AUTOSAR XML (schema 00044)
package /E40_Platform_System_SystemPackage/Components
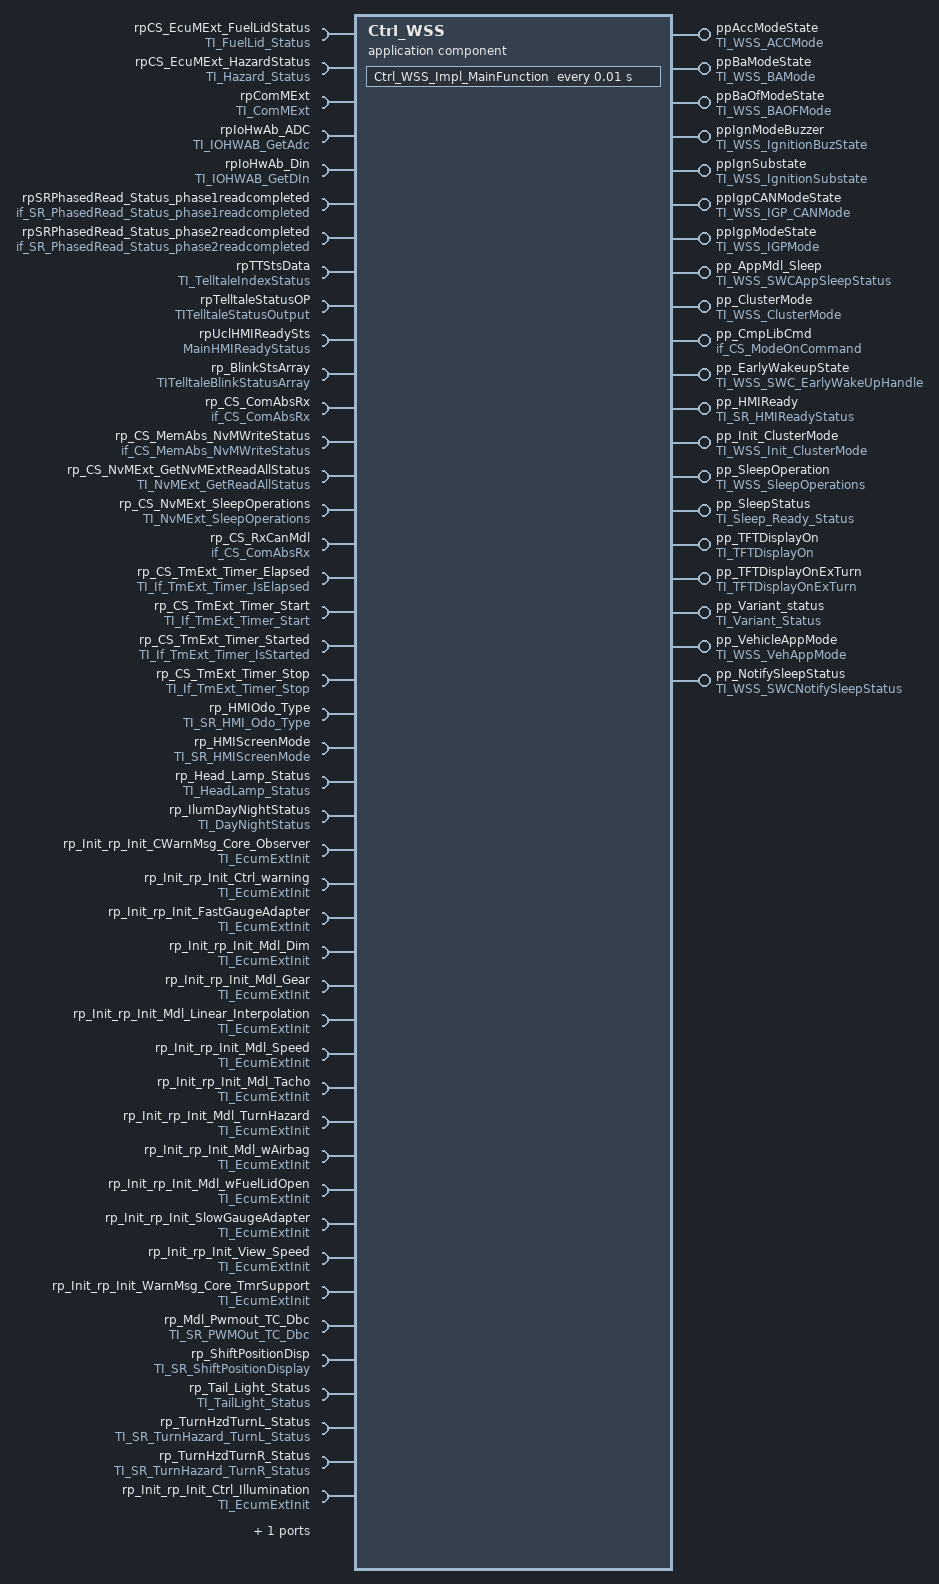
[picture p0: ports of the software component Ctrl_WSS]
  application sw component type Ctrl_WSS
    19 x provide port:
      ppAccModeState: nonqueued-sender-com-spec{data-element=WSSAccState, init-value=constant-reference=Ctrl_WSSWSSAccStateValue0}, provided-interface=TI_WSS_ACCMode
      ppBaModeState: nonqueued-sender-com-spec{data-element=WSSBaState, init-value=constant-reference=Ctrl_WSSWSSBaStateValue0}, provided-interface=TI_WSS_BAMode
      ppBaOfModeState: nonqueued-sender-com-spec{data-element=WSSBaOfState, init-value=constant-reference=Ctrl_WSSWSSBaOfStateValue0}, provided-interface=TI_WSS_BAOFMode
      ppIgnModeBuzzer: nonqueued-sender-com-spec{data-element=IgnitioBuznstate, init-value=constant-reference=Ctrl_WSSIgnitioBuznstateValue0}, provided-interface=TI_WSS_IgnitionBuzState
      ppIgnSubstate: nonqueued-sender-com-spec{data-element=IgnitionSubstate, init-value=constant-reference=Ctrl_WSSIgnitionSubstateValue0}, provided-interface=TI_WSS_IgnitionSubstate
      ppIgpCANModeState: nonqueued-sender-com-spec{data-element=WSSIGPCANState, init-value=constant-reference=Ctrl_WSSWSSIGPCANStateValue0}, provided-interface=TI_WSS_IGP_CANMode
      ppIgpModeState: nonqueued-sender-com-spec{data-element=WSSIGPState, init-value=constant-reference=Ctrl_WSSWSSIGPStateValue0}, provided-interface=TI_WSS_IGPMode
      pp_AppMdl_Sleep: server-com-spec{operation=SWCSleepStatus, queue-length=1}, provided-interface=TI_WSS_SWCAppSleepStatus
      pp_ClusterMode: nonqueued-sender-com-spec{data-element=WSSCurrentClusterMode, init-value=constant-reference=Ctrl_WSSWSSCurrentClusterModeValue0}, provided-interface=TI_WSS_ClusterMode
      pp_CmpLibCmd: server-com-spec{operation=Impl_OnCommand, queue-length=1}, provided-interface=if_CS_ModeOnCommand
      pp_EarlyWakeupState: server-com-spec{operation=SWCEarlyWakeUpHandle, queue-length=1}, provided-interface=TI_WSS_SWC_EarlyWakeUpHandle
      pp_HMIReady: nonqueued-sender-com-spec{data-element=HMI_ReadyStatus, init-value=constant-reference=Ctrl_WSSHMI_ReadyStatusValue0}, provided-interface=TI_SR_HMIReadyStatus
      pp_Init_ClusterMode: nonqueued-sender-com-spec{data-element=WSSCurrentClusterInitMode, init-value=constant-reference=Ctrl_WSSWSSCurrentClusterInitModeValue0}, provided-interface=TI_WSS_Init_ClusterMode
      pp_SleepOperation: provided-interface=TI_WSS_SleepOperations
        provided-com-specs:
          operation=CtrlWSS_CancelSleep, queue-length=1
          operation=CtrlWSS_ReadytoSleep, queue-length=1
          operation=CtrlWSS_RequestSleep, queue-length=1
      pp_SleepStatus: nonqueued-sender-com-spec{data-element=Sleep_Status, init-value=constant-reference=Ctrl_WSSSleep_StatusValue0}, provided-interface=TI_Sleep_Ready_Status
      pp_TFTDisplayOn: nonqueued-sender-com-spec{data-element=TFTDisplayOn, init-value=constant-reference=Ctrl_WSSTFTDisplayOnValue0}, provided-interface=TI_TFTDisplayOn
      pp_TFTDisplayOnExTurn: nonqueued-sender-com-spec{data-element=TFTDisplayOnExTurn, init-value=constant-reference=Ctrl_WSSTFTDisplayOnExTurnValue0}, provided-interface=TI_TFTDisplayOnExTurn
      pp_Variant_status: server-com-spec{operation=GetVariant_Status, queue-length=1}, provided-interface=TI_Variant_Status
      pp_VehicleAppMode: nonqueued-sender-com-spec{data-element=WSSCurrentVehicleState, init-value=constant-reference=Ctrl_WSSWSSCurrentVehicleStateValue0}, provided-interface=TI_WSS_VehAppMode
    45 x require port:
      rpCS_EcuMExt_FuelLidStatus: queued-receiver-com-spec{data-element=FuelLidStatus, queue-length=15}, required-interface=TI_FuelLid_Status
      rpCS_EcuMExt_HazardStatus: queued-receiver-com-spec{data-element=HazardStatus, queue-length=15}, required-interface=TI_Hazard_Status
      rpComMExt: required-interface=TI_ComMExt
        required-com-specs:
          CAN_ActivateSilentCommunication
          CAN_CommControlActivateRx
          CAN_CommControlActivateTx
          CAN_CommControlDeActivateRx
          CAN_CommControlDeActivateTx
          CAN_CommControlSetDone
          CAN_DeActivateSilentCommunication
          CAN_GetCurrentComMode
          CAN_ReleaseCommunication
          CAN_RequestCommunication
          GetBusOffStatus
          Get_MCAN_ERR_PIN_Status
          Init
      rpIoHwAb_ADC: required-com-specs=[GetAsyncRawAdc, GetProcessedAdc, GetSyncRawAdc], required-interface=TI_IOHWAB_GetAdc
      rpIoHwAb_Din: required-com-specs=[GetAsyncRawInput, GetInputGroup, GetProcessedInput, GetSyncRawInput], required-interface=TI_IOHWAB_GetDIn
      rpSRPhasedRead_Status_phase1readcompleted: nonqueued-receiver-com-spec{data-element=PhasedRead_Status_phase1readcompleted, init-value=constant-reference=Ctrl_WSSPhasedRead_Status_phase1readcompletedValue0}, required-interface=if_SR_PhasedRead_Status_phase1readcompleted
      rpSRPhasedRead_Status_phase2readcompleted: nonqueued-receiver-com-spec{data-element=PhasedRead_Status_phase2readcompleted, init-value=constant-reference=Ctrl_WSSPhasedRead_Status_phase2readcompletedValue0}, required-interface=if_SR_PhasedRead_Status_phase2readcompleted
      rpTTStsData: required-interface=TI_TelltaleIndexStatus
        required-com-specs:
          data-element=TTIndex, init-value=constant-reference=Ctrl_WSSTTIndexValue0
          data-element=TTStatus, init-value=constant-reference=Ctrl_WSSTTStatusValue0
      rpTelltaleStatusOP: nonqueued-receiver-com-spec{data-element=TelltaleOpArray, init-value=constant-reference=Ctrl_WSSTelltaleOpArrayValue0}, required-interface=TITelltaleStatusOutput
      rpUclHMIReadySts: queued-receiver-com-spec{data-element=MainHMIReadyStatusData, queue-length=5}, required-interface=MainHMIReadyStatus
      rp_BlinkStsArray: required-interface=TITelltaleBlinkStatusArray
        required-com-specs:
          data-element=TTBlinkStatusArray, init-value=constant-reference=Ctrl_WSSTTBlinkStatusArrayValue0
          data-element=TTdummyDataForTypes, init-value=constant-reference=Ctrl_WSSTTdummyDataForTypesValue0
      rp_CS_ComAbsRx: required-interface=if_CS_ComAbsRx
        required-com-specs:
          RxCan_GetSignalValue
          RxCan_GetSignalValueU8Arr
          RxCan_SetSignalInitValue
          RxCan_SetSignalInitValueU8Arr
          RxCan_SignalClearJustRcvdStatus
          RxCan_SignalGetJustRcvdStatus
          RxCan_SignalInvalidProcessingControl
          RxCan_SignalMissingProcessingControl
          RxCan_SignalNRProcessingControl
      rp_CS_MemAbs_NvMWriteStatus: client-com-spec=NvmWriteStatus, required-interface=if_CS_MemAbs_NvMWriteStatus
      rp_CS_NvMExt_GetNvMExtReadAllStatus: client-com-spec=NvmExt_GetNvMReadAllStatus, required-interface=TI_NvMExt_GetReadAllStatus
      rp_CS_NvMExt_SleepOperations: required-com-specs=[NvMExt_CancelSleep, NvMExt_ReadytoSleep, NvMExt_RequestSleep], required-interface=TI_NvMExt_SleepOperations
      rp_CS_RxCanMdl: required-interface=if_CS_ComAbsRx
        required-com-specs:
          RxCan_GetSignalValue
          RxCan_GetSignalValueU8Arr
          RxCan_SetSignalInitValue
          RxCan_SetSignalInitValueU8Arr
          RxCan_SignalClearJustRcvdStatus
          RxCan_SignalGetJustRcvdStatus
          RxCan_SignalInvalidProcessingControl
          RxCan_SignalMissingProcessingControl
          RxCan_SignalNRProcessingControl
      rp_CS_TmExt_Timer_Elapsed: client-com-spec=Timer_IsElapsed, required-interface=TI_If_TmExt_Timer_IsElapsed
      rp_CS_TmExt_Timer_Start: client-com-spec=Timer_Start, required-interface=TI_If_TmExt_Timer_Start
      rp_CS_TmExt_Timer_Started: client-com-spec=Timer_IsStarted, required-interface=TI_If_TmExt_Timer_IsStarted
      rp_CS_TmExt_Timer_Stop: client-com-spec=Timer_Stop, required-interface=TI_If_TmExt_Timer_Stop
      rp_HMIOdo_Type: nonqueued-receiver-com-spec{data-element=HMI_OdoType, init-value=constant-reference=Ctrl_WSSHMI_OdoTypeValue0}, required-interface=TI_SR_HMI_Odo_Type
      rp_HMIScreenMode: nonqueued-receiver-com-spec{data-element=HMIScreenMode_Status, init-value=constant-reference=Ctrl_WSSHMIScreenMode_StatusValue0}, required-interface=TI_SR_HMIScreenMode
      rp_Head_Lamp_Status: nonqueued-receiver-com-spec{data-element=Head_Lamp_st, init-value=constant-reference=Ctrl_WSSHead_Lamp_stValue0}, required-interface=TI_HeadLamp_Status
      rp_IlumDayNightStatus: nonqueued-receiver-com-spec{data-element=illumDNStatus, init-value=constant-reference=Ctrl_WSSillumDNStatusValue0}, required-interface=TI_DayNightStatus
      rp_Init_rp_Init_CWarnMsg_Core_Observer: client-com-spec=Init, required-interface=TI_EcumExtInit
      rp_Init_rp_Init_Ctrl_warning: client-com-spec=Init, required-interface=TI_EcumExtInit
      rp_Init_rp_Init_FastGaugeAdapter: client-com-spec=Init, required-interface=TI_EcumExtInit
      rp_Init_rp_Init_Mdl_Dim: client-com-spec=Init, required-interface=TI_EcumExtInit
      rp_Init_rp_Init_Mdl_Gear: client-com-spec=Init, required-interface=TI_EcumExtInit
      rp_Init_rp_Init_Mdl_Linear_Interpolation: client-com-spec=Init, required-interface=TI_EcumExtInit
      rp_Init_rp_Init_Mdl_Speed: client-com-spec=Init, required-interface=TI_EcumExtInit
      rp_Init_rp_Init_Mdl_Tacho: client-com-spec=Init, required-interface=TI_EcumExtInit
      rp_Init_rp_Init_Mdl_TurnHazard: client-com-spec=Init, required-interface=TI_EcumExtInit
      rp_Init_rp_Init_Mdl_wAirbag: client-com-spec=Init, required-interface=TI_EcumExtInit
      rp_Init_rp_Init_Mdl_wFuelLidOpen: client-com-spec=Init, required-interface=TI_EcumExtInit
      rp_Init_rp_Init_SlowGaugeAdapter: client-com-spec=Init, required-interface=TI_EcumExtInit
      rp_Init_rp_Init_View_Speed: client-com-spec=Init, required-interface=TI_EcumExtInit
      rp_Init_rp_Init_WarnMsg_Core_TmrSupport: client-com-spec=Init, required-interface=TI_EcumExtInit
      rp_Mdl_Pwmout_TC_Dbc: nonqueued-receiver-com-spec{data-element=PWMOut_TC_Dbc, init-value=constant-reference=Ctrl_WSSPWMOut_TC_DbcValue0}, required-interface=TI_SR_PWMOut_TC_Dbc
      rp_ShiftPositionDisp: nonqueued-receiver-com-spec{data-element=ShiftPositionDisplay, init-value=constant-reference=Ctrl_WSSShiftPositionDisplayValue0}, required-interface=TI_SR_ShiftPositionDisplay
      rp_Tail_Light_Status: nonqueued-receiver-com-spec{data-element=Tail_Light_st, init-value=constant-reference=Ctrl_WSSTail_Light_stValue0}, required-interface=TI_TailLight_Status
      rp_TurnHzdTurnL_Status: nonqueued-receiver-com-spec{data-element=LeftIndicatorSts, init-value=constant-reference=Ctrl_WSSLeftIndicatorStsValue0}, required-interface=TI_SR_TurnHazard_TurnL_Status
      rp_TurnHzdTurnR_Status: nonqueued-receiver-com-spec{data-element=RightIndicatorSts, init-value=constant-reference=Ctrl_WSSRightIndicatorStsValue0}, required-interface=TI_SR_TurnHazard_TurnR_Status
      rp_Init_rp_Init_Ctrl_Illumination: client-com-spec=Init, required-interface=TI_EcumExtInit
      rpSRPhasedRead_Status_phase3readcompleted: nonqueued-receiver-com-spec{data-element=PhasedRead_Status_phase3readcompleted, init-value=constant-reference=Ctrl_WSSPhasedRead_Status_phase3readcompletedValue0}, required-interface=if_SR_PhasedRead_Status_phase3readcompleted
    provide port pp_NotifySleepStatus: server-com-spec{operation=CtrlWSS_NotifyNetworkSleep, queue-length=1}, provided-interface=TI_WSS_SWCNotifySleepStatus
    behavior IB_Ctrl_WSS
      4 x operation invoked event:
        OIE_pp_SleepOperation_CtrlWSS_CancelSleepTrigByCtrlWSS_CancelSleep: start-on-event=CtrlWSS_CancelSleep, operation=pp_SleepOperation.CtrlWSS_CancelSleep
        OIE_pp_SleepOperation_CtrlWSS_ReadytoSleepTrigByCtrlWSS_ReadytoSleep: start-on-event=CtrlWSS_ReadytoSleep, operation=pp_SleepOperation.CtrlWSS_ReadytoSleep
        OIE_pp_SleepOperation_CtrlWSS_RequestSleepTrigByCtrlWSS_RequestSleep: start-on-event=CtrlWSS_RequestSleep, operation=pp_SleepOperation.CtrlWSS_RequestSleep
        OIE_pp_Variant_status_Ctrl_WSS_GetVariant_StatusTrigByGetVariant_Status: start-on-event=Ctrl_WSS_GetVariant_Status, operation=pp_Variant_status.GetVariant_Status
      timing event TECtrl_WSS_Impl_MainFunction: start-on-event=Ctrl_WSS_Impl_MainFunction, period=0.01
      4 x operation invoked event:
        OIE_pp_CmpLibCmd_Ctrl_WSS_Impl_OnCommandTrigByImpl_OnCommand: start-on-event=Ctrl_WSS_Impl_OnCommand, operation=pp_CmpLibCmd.Impl_OnCommand
        OIE_pp_EarlyWakeupState_Ctrl_WSS_SWCEarlyWakeUpHandleTrigBySWCEarlyWakeUpHandle: start-on-event=Ctrl_WSS_SWCEarlyWakeUpHandle, operation=pp_EarlyWakeupState.SWCEarlyWakeUpHandle
        OIE_pp_AppMdl_Sleep_Ctrl_WSS_SWCSleepStatusTrigBySWCSleepStatus: start-on-event=Ctrl_WSS_SWCSleepStatus, operation=pp_AppMdl_Sleep.SWCSleepStatus
        OIE_pp_NotifySleepStatus_Ctrl_WSS_CtrlWSS_NotifyNetworkSleepTrigByCtrlWSS_NotifyNetworkSleep: start-on-event=Ctrl_WSS_CtrlWSS_NotifyNetworkSleep, operation=pp_NotifySleepStatus.CtrlWSS_NotifyNetworkSleep
      port-api-options:
        enable-take-address=false, indirect-api=false, port=ppAccModeState
        enable-take-address=false, indirect-api=false, port=ppBaModeState
        enable-take-address=false, indirect-api=false, port=ppBaOfModeState
        enable-take-address=false, indirect-api=false, port=ppIgnModeBuzzer
        enable-take-address=false, indirect-api=false, port=ppIgnSubstate
        enable-take-address=false, indirect-api=false, port=ppIgpCANModeState
        enable-take-address=false, indirect-api=false, port=ppIgpModeState
        enable-take-address=false, indirect-api=false, port=pp_AppMdl_Sleep
        enable-take-address=false, indirect-api=false, port=pp_ClusterMode
        enable-take-address=false, indirect-api=false, port=pp_CmpLibCmd
        enable-take-address=false, indirect-api=false, port=pp_EarlyWakeupState
        enable-take-address=false, indirect-api=false, port=pp_HMIReady
        enable-take-address=false, indirect-api=false, port=pp_Init_ClusterMode
        enable-take-address=false, indirect-api=false, port=pp_SleepOperation
        enable-take-address=false, indirect-api=false, port=pp_SleepStatus
        enable-take-address=false, indirect-api=false, port=pp_TFTDisplayOn
        enable-take-address=false, indirect-api=false, port=pp_TFTDisplayOnExTurn
        enable-take-address=false, indirect-api=false, port=pp_Variant_status
        enable-take-address=false, indirect-api=false, port=pp_VehicleAppMode
        enable-take-address=false, indirect-api=false, port=rpCS_EcuMExt_FuelLidStatus
        enable-take-address=false, indirect-api=false, port=rpCS_EcuMExt_HazardStatus
        enable-take-address=false, indirect-api=false, port=rpComMExt
        enable-take-address=false, indirect-api=false, port=rpIoHwAb_ADC
        enable-take-address=false, indirect-api=false, port=rpIoHwAb_Din
        enable-take-address=false, indirect-api=false, port=rpSRPhasedRead_Status_phase1readcompleted
        enable-take-address=false, indirect-api=false, port=rpSRPhasedRead_Status_phase2readcompleted
        enable-take-address=false, indirect-api=false, port=rpTTStsData
        enable-take-address=false, indirect-api=false, port=rpTelltaleStatusOP
        enable-take-address=false, indirect-api=false, port=rpUclHMIReadySts
        enable-take-address=false, indirect-api=false, port=rp_BlinkStsArray
        enable-take-address=false, indirect-api=false, port=rp_CS_ComAbsRx
        enable-take-address=false, indirect-api=false, port=rp_CS_MemAbs_NvMWriteStatus
        enable-take-address=false, indirect-api=false, port=rp_CS_NvMExt_GetNvMExtReadAllStatus
        enable-take-address=false, indirect-api=false, port=rp_CS_NvMExt_SleepOperations
        enable-take-address=false, indirect-api=false, port=rp_CS_RxCanMdl
        enable-take-address=false, indirect-api=false, port=rp_CS_TmExt_Timer_Elapsed
        enable-take-address=false, indirect-api=false, port=rp_CS_TmExt_Timer_Start
        enable-take-address=false, indirect-api=false, port=rp_CS_TmExt_Timer_Started
        enable-take-address=false, indirect-api=false, port=rp_CS_TmExt_Timer_Stop
        enable-take-address=false, indirect-api=false, port=rp_HMIOdo_Type
        enable-take-address=false, indirect-api=false, port=rp_HMIScreenMode
        enable-take-address=false, indirect-api=false, port=rp_Head_Lamp_Status
        enable-take-address=false, indirect-api=false, port=rp_IlumDayNightStatus
        enable-take-address=false, indirect-api=false, port=rp_Init_rp_Init_CWarnMsg_Core_Observer
        enable-take-address=false, indirect-api=false, port=rp_Init_rp_Init_Ctrl_warning
        enable-take-address=false, indirect-api=false, port=rp_Init_rp_Init_FastGaugeAdapter
        enable-take-address=false, indirect-api=false, port=rp_Init_rp_Init_Mdl_Dim
        enable-take-address=false, indirect-api=false, port=rp_Init_rp_Init_Mdl_Gear
        enable-take-address=false, indirect-api=false, port=rp_Init_rp_Init_Mdl_Linear_Interpolation
        enable-take-address=false, indirect-api=false, port=rp_Init_rp_Init_Mdl_Speed
        enable-take-address=false, indirect-api=false, port=rp_Init_rp_Init_Mdl_Tacho
        enable-take-address=false, indirect-api=false, port=rp_Init_rp_Init_Mdl_TurnHazard
        enable-take-address=false, indirect-api=false, port=rp_Init_rp_Init_Mdl_wAirbag
        enable-take-address=false, indirect-api=false, port=rp_Init_rp_Init_Mdl_wFuelLidOpen
        enable-take-address=false, indirect-api=false, port=rp_Init_rp_Init_SlowGaugeAdapter
        enable-take-address=false, indirect-api=false, port=rp_Init_rp_Init_View_Speed
        enable-take-address=false, indirect-api=false, port=rp_Init_rp_Init_WarnMsg_Core_TmrSupport
        enable-take-address=false, indirect-api=false, port=rp_Mdl_Pwmout_TC_Dbc
        enable-take-address=false, indirect-api=false, port=rp_ShiftPositionDisp
        enable-take-address=false, indirect-api=false, port=rp_Tail_Light_Status
        enable-take-address=false, indirect-api=false, port=rp_TurnHzdTurnL_Status
        enable-take-address=false, indirect-api=false, port=rp_TurnHzdTurnR_Status
        enable-take-address=false, indirect-api=false, port=rp_Init_rp_Init_Ctrl_Illumination
        enable-take-address=false, indirect-api=false, port=rpSRPhasedRead_Status_phase3readcompleted
        enable-take-address=false, indirect-api=false, port=pp_NotifySleepStatus
      9 x runnable, all with can-be-invoked-concurrently=true:
        CtrlWSS_CancelSleep
        CtrlWSS_ReadytoSleep
        CtrlWSS_RequestSleep
        Ctrl_WSS_GetVariant_Status
        Ctrl_WSS_Impl_MainFunction
          data-receive-point-by-arguments:
            20 x access:
              DRP_rpCS_EcuMExt_FuelLidStatus_FuelLidStatus: accessed-variable=rpCS_EcuMExt_FuelLidStatus.FuelLidStatus
              DRP_rpCS_EcuMExt_HazardStatus_HazardStatus: accessed-variable=rpCS_EcuMExt_HazardStatus.HazardStatus
              DRA_rpSRPhasedRead_Status_phase1readcompleted_PhasedRead_Status_phase1readcompleted: accessed-variable=rpSRPhasedRead_Status_phase1readcompleted.PhasedRead_Status_phase1readcompleted
              DRA_rpSRPhasedRead_Status_phase2readcompleted_PhasedRead_Status_phase2readcompleted: accessed-variable=rpSRPhasedRead_Status_phase2readcompleted.PhasedRead_Status_phase2readcompleted
              DRA_rpTTStsData_TTIndex: accessed-variable=rpTTStsData.TTIndex
              DRA_rpTTStsData_TTStatus: accessed-variable=rpTTStsData.TTStatus
              DRA_rpTelltaleStatusOP_TelltaleOpArray: accessed-variable=rpTelltaleStatusOP.TelltaleOpArray
              DRA_rp_BlinkStsArray_TTBlinkStatusArray: accessed-variable=rp_BlinkStsArray.TTBlinkStatusArray
              DRA_rp_BlinkStsArray_TTdummyDataForTypes: accessed-variable=rp_BlinkStsArray.TTdummyDataForTypes
              DRA_rp_HMIOdo_Type_HMI_OdoType: accessed-variable=rp_HMIOdo_Type.HMI_OdoType
              DRA_rp_HMIScreenMode_HMIScreenMode_Status: accessed-variable=rp_HMIScreenMode.HMIScreenMode_Status
              DRA_rp_Head_Lamp_Status_Head_Lamp_st: accessed-variable=rp_Head_Lamp_Status.Head_Lamp_st
              DRA_rp_IlumDayNightStatus_illumDNStatus: accessed-variable=rp_IlumDayNightStatus.illumDNStatus
              DRA_rp_Mdl_Pwmout_TC_Dbc_PWMOut_TC_Dbc: accessed-variable=rp_Mdl_Pwmout_TC_Dbc.PWMOut_TC_Dbc
              DRA_rp_ShiftPositionDisp_ShiftPositionDisplay: accessed-variable=rp_ShiftPositionDisp.ShiftPositionDisplay
              DRA_rp_Tail_Light_Status_Tail_Light_st: accessed-variable=rp_Tail_Light_Status.Tail_Light_st
              DRA_rp_TurnHzdTurnL_Status_LeftIndicatorSts: accessed-variable=rp_TurnHzdTurnL_Status.LeftIndicatorSts
              DRA_rp_TurnHzdTurnR_Status_RightIndicatorSts: accessed-variable=rp_TurnHzdTurnR_Status.RightIndicatorSts
              DRP_rpUclHMIReadySts_MainHMIReadyStatusData: accessed-variable=rpUclHMIReadySts.MainHMIReadyStatusData
              DRA_rpSRPhasedRead_Status_phase3readcompleted_PhasedRead_Status_phase3readcompleted: accessed-variable=rpSRPhasedRead_Status_phase3readcompleted.PhasedRead_Status_phase3readcompleted
          data-send-points:
            14 x access:
              DWA_ppAccModeState_WSSAccState: accessed-variable=ppAccModeState.WSSAccState
              DWA_ppBaModeState_WSSBaState: accessed-variable=ppBaModeState.WSSBaState
              DWA_ppBaOfModeState_WSSBaOfState: accessed-variable=ppBaOfModeState.WSSBaOfState
              DWA_ppIgnModeBuzzer_IgnitioBuznstate: accessed-variable=ppIgnModeBuzzer.IgnitioBuznstate
              DWA_ppIgnSubstate_IgnitionSubstate: accessed-variable=ppIgnSubstate.IgnitionSubstate
              DWA_ppIgpCANModeState_WSSIGPCANState: accessed-variable=ppIgpCANModeState.WSSIGPCANState
              DWA_ppIgpModeState_WSSIGPState: accessed-variable=ppIgpModeState.WSSIGPState
              DWA_pp_ClusterMode_WSSCurrentClusterMode: accessed-variable=pp_ClusterMode.WSSCurrentClusterMode
              DWA_pp_HMIReady_HMI_ReadyStatus: accessed-variable=pp_HMIReady.HMI_ReadyStatus
              DWA_pp_Init_ClusterMode_WSSCurrentClusterInitMode: accessed-variable=pp_Init_ClusterMode.WSSCurrentClusterInitMode
              DWA_pp_SleepStatus_Sleep_Status: accessed-variable=pp_SleepStatus.Sleep_Status
              DWA_pp_TFTDisplayOn_TFTDisplayOn: accessed-variable=pp_TFTDisplayOn.TFTDisplayOn
              DWA_pp_TFTDisplayOnExTurn_TFTDisplayOnExTurn: accessed-variable=pp_TFTDisplayOnExTurn.TFTDisplayOnExTurn
              DWA_pp_VehicleAppMode_WSSCurrentVehicleState: accessed-variable=pp_VehicleAppMode.WSSCurrentVehicleState
          62 x sync call:
            OA_rpComMExt_Get_MCAN_ERR_PIN_Status: operation=rpComMExt.Get_MCAN_ERR_PIN_Status
            OA_rpComMExt_Init: operation=rpComMExt.Init
            OA_rpComMExt_GetBusOffStatus: operation=rpComMExt.GetBusOffStatus
            OA_rpComMExt_CAN_RequestCommunication: operation=rpComMExt.CAN_RequestCommunication
            OA_rpComMExt_CAN_GetCurrentComMode: operation=rpComMExt.CAN_GetCurrentComMode
            OA_rpComMExt_CAN_ReleaseCommunication: operation=rpComMExt.CAN_ReleaseCommunication
            OA_rpComMExt_CAN_DeActivateSilentCommunication: operation=rpComMExt.CAN_DeActivateSilentCommunication
            OA_rpComMExt_CAN_CommControlSetDone: operation=rpComMExt.CAN_CommControlSetDone
            OA_rpComMExt_CAN_CommControlDeActivateTx: operation=rpComMExt.CAN_CommControlDeActivateTx
            OA_rpComMExt_CAN_CommControlDeActivateRx: operation=rpComMExt.CAN_CommControlDeActivateRx
            OA_rpComMExt_CAN_ActivateSilentCommunication: operation=rpComMExt.CAN_ActivateSilentCommunication
            OA_rpComMExt_CAN_CommControlActivateRx: operation=rpComMExt.CAN_CommControlActivateRx
            OA_rpComMExt_CAN_CommControlActivateTx: operation=rpComMExt.CAN_CommControlActivateTx
            OA_rpIoHwAb_ADC_GetAsyncRawAdc: operation=rpIoHwAb_ADC.GetAsyncRawAdc
            OA_rpIoHwAb_ADC_GetSyncRawAdc: operation=rpIoHwAb_ADC.GetSyncRawAdc
            OA_rpIoHwAb_ADC_GetProcessedAdc: operation=rpIoHwAb_ADC.GetProcessedAdc
            OA_rpIoHwAb_Din_GetAsyncRawInput: operation=rpIoHwAb_Din.GetAsyncRawInput
            OA_rpIoHwAb_Din_GetProcessedInput: operation=rpIoHwAb_Din.GetProcessedInput
            OA_rpIoHwAb_Din_GetSyncRawInput: operation=rpIoHwAb_Din.GetSyncRawInput
            OA_rpIoHwAb_Din_GetInputGroup: operation=rpIoHwAb_Din.GetInputGroup
            OA_rp_CS_ComAbsRx_RxCan_GetSignalValueU8Arr: operation=rp_CS_ComAbsRx.RxCan_GetSignalValueU8Arr
            OA_rp_CS_ComAbsRx_RxCan_SetSignalInitValue: operation=rp_CS_ComAbsRx.RxCan_SetSignalInitValue
            OA_rp_CS_ComAbsRx_RxCan_SetSignalInitValueU8Arr: operation=rp_CS_ComAbsRx.RxCan_SetSignalInitValueU8Arr
            OA_rp_CS_ComAbsRx_RxCan_SignalInvalidProcessingControl: operation=rp_CS_ComAbsRx.RxCan_SignalInvalidProcessingControl
            OA_rp_CS_ComAbsRx_RxCan_SignalMissingProcessingControl: operation=rp_CS_ComAbsRx.RxCan_SignalMissingProcessingControl
            OA_rp_CS_ComAbsRx_RxCan_SignalNRProcessingControl: operation=rp_CS_ComAbsRx.RxCan_SignalNRProcessingControl
            OA_rp_CS_ComAbsRx_RxCan_SignalGetJustRcvdStatus: operation=rp_CS_ComAbsRx.RxCan_SignalGetJustRcvdStatus
            OA_rp_CS_ComAbsRx_RxCan_SignalClearJustRcvdStatus: operation=rp_CS_ComAbsRx.RxCan_SignalClearJustRcvdStatus
            OA_rp_CS_ComAbsRx_RxCan_GetSignalValue: operation=rp_CS_ComAbsRx.RxCan_GetSignalValue
            OA_rp_CS_MemAbs_NvMWriteStatus_NvmWriteStatus: operation=rp_CS_MemAbs_NvMWriteStatus.NvmWriteStatus
            OA_rp_CS_NvMExt_GetNvMExtReadAllStatus_NvmExt_GetNvMReadAllStatus: operation=rp_CS_NvMExt_GetNvMExtReadAllStatus.NvmExt_GetNvMReadAllStatus
            OA_rp_CS_NvMExt_SleepOperations_NvMExt_ReadytoSleep: operation=rp_CS_NvMExt_SleepOperations.NvMExt_ReadytoSleep
            OA_rp_CS_NvMExt_SleepOperations_NvMExt_RequestSleep: operation=rp_CS_NvMExt_SleepOperations.NvMExt_RequestSleep
            OA_rp_CS_NvMExt_SleepOperations_NvMExt_CancelSleep: operation=rp_CS_NvMExt_SleepOperations.NvMExt_CancelSleep
            OA_rp_CS_RxCanMdl_RxCan_GetSignalValueU8Arr: operation=rp_CS_RxCanMdl.RxCan_GetSignalValueU8Arr
            OA_rp_CS_RxCanMdl_RxCan_SetSignalInitValue: operation=rp_CS_RxCanMdl.RxCan_SetSignalInitValue
            OA_rp_CS_RxCanMdl_RxCan_SetSignalInitValueU8Arr: operation=rp_CS_RxCanMdl.RxCan_SetSignalInitValueU8Arr
            OA_rp_CS_RxCanMdl_RxCan_SignalInvalidProcessingControl: operation=rp_CS_RxCanMdl.RxCan_SignalInvalidProcessingControl
            OA_rp_CS_RxCanMdl_RxCan_SignalMissingProcessingControl: operation=rp_CS_RxCanMdl.RxCan_SignalMissingProcessingControl
            OA_rp_CS_RxCanMdl_RxCan_SignalNRProcessingControl: operation=rp_CS_RxCanMdl.RxCan_SignalNRProcessingControl
            OA_rp_CS_RxCanMdl_RxCan_SignalGetJustRcvdStatus: operation=rp_CS_RxCanMdl.RxCan_SignalGetJustRcvdStatus
            OA_rp_CS_RxCanMdl_RxCan_SignalClearJustRcvdStatus: operation=rp_CS_RxCanMdl.RxCan_SignalClearJustRcvdStatus
            OA_rp_CS_RxCanMdl_RxCan_GetSignalValue: operation=rp_CS_RxCanMdl.RxCan_GetSignalValue
            OA_rp_CS_TmExt_Timer_Elapsed_Timer_IsElapsed: operation=rp_CS_TmExt_Timer_Elapsed.Timer_IsElapsed
            OA_rp_CS_TmExt_Timer_Start_Timer_Start: operation=rp_CS_TmExt_Timer_Start.Timer_Start
            OA_rp_CS_TmExt_Timer_Started_Timer_IsStarted: operation=rp_CS_TmExt_Timer_Started.Timer_IsStarted
            OA_rp_CS_TmExt_Timer_Stop_Timer_Stop: operation=rp_CS_TmExt_Timer_Stop.Timer_Stop
            OA_rp_Init_rp_Init_CWarnMsg_Core_Observer_Init: operation=rp_Init_rp_Init_CWarnMsg_Core_Observer.Init
            OA_rp_Init_rp_Init_Ctrl_warning_Init: operation=rp_Init_rp_Init_Ctrl_warning.Init
            OA_rp_Init_rp_Init_FastGaugeAdapter_Init: operation=rp_Init_rp_Init_FastGaugeAdapter.Init
            OA_rp_Init_rp_Init_Mdl_Dim_Init: operation=rp_Init_rp_Init_Mdl_Dim.Init
            OA_rp_Init_rp_Init_Mdl_Gear_Init: operation=rp_Init_rp_Init_Mdl_Gear.Init
            OA_rp_Init_rp_Init_Mdl_Linear_Interpolation_Init: operation=rp_Init_rp_Init_Mdl_Linear_Interpolation.Init
            OA_rp_Init_rp_Init_Mdl_Speed_Init: operation=rp_Init_rp_Init_Mdl_Speed.Init
            OA_rp_Init_rp_Init_Mdl_Tacho_Init: operation=rp_Init_rp_Init_Mdl_Tacho.Init
            OA_rp_Init_rp_Init_Mdl_TurnHazard_Init: operation=rp_Init_rp_Init_Mdl_TurnHazard.Init
            OA_rp_Init_rp_Init_Mdl_wAirbag_Init: operation=rp_Init_rp_Init_Mdl_wAirbag.Init
            OA_rp_Init_rp_Init_Mdl_wFuelLidOpen_Init: operation=rp_Init_rp_Init_Mdl_wFuelLidOpen.Init
            OA_rp_Init_rp_Init_SlowGaugeAdapter_Init: operation=rp_Init_rp_Init_SlowGaugeAdapter.Init
            OA_rp_Init_rp_Init_View_Speed_Init: operation=rp_Init_rp_Init_View_Speed.Init
            OA_rp_Init_rp_Init_WarnMsg_Core_TmrSupport_Init: operation=rp_Init_rp_Init_WarnMsg_Core_TmrSupport.Init
            OA_rp_Init_rp_Init_Ctrl_Illumination_Init: operation=rp_Init_rp_Init_Ctrl_Illumination.Init
        Ctrl_WSS_Impl_OnCommand
        Ctrl_WSS_SWCEarlyWakeUpHandle
        Ctrl_WSS_SWCSleepStatus
        Ctrl_WSS_CtrlWSS_NotifyNetworkSleep
  swc implementation IMPL_Ctrl_WSS: behavior=IB_Ctrl_WSS
